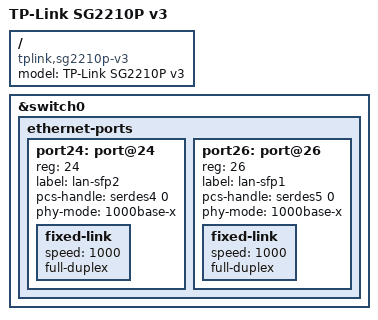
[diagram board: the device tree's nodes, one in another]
// SPDX-License-Identifier: GPL-2.0-or-later

#include "rtl8380_tplink_sg2xxx.dtsi"

/ {
	compatible = "tplink,sg2210p-v3", "realtek,rtl838x-soc";
	model = "TP-Link SG2210P v3";
};

&switch0 {
	ethernet-ports {
		port24: port@24 {
			reg = <24>;
			label = "lan-sfp2";
			pcs-handle = <&serdes4 0>;
			phy-mode = "1000base-x";
			fixed-link {
				speed = <1000>;
				full-duplex;
			};
		};

		port26: port@26 {
			reg = <26>;
			label = "lan-sfp1";
			pcs-handle = <&serdes5 0>;
			phy-mode = "1000base-x";
			fixed-link {
				speed = <1000>;
				full-duplex;
			};
		};
	};
};

